# MDR32F2C10 register map
File version: 1.0.1
Registers are 32-bit, read-write, no defined reset value unless marked. A register's access mark holds for its fields unless they carry their own. Offsets are from the block's base; [hi:lo] are bit positions; {n}, {i} and the like mark numbered series.

## MDR_CANFD — MDR_CANFD description
Base 0x40086000
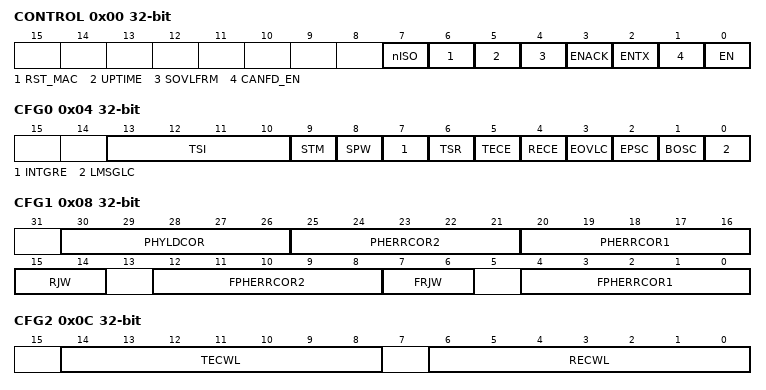
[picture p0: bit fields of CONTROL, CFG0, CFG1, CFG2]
0x00 CONTROL — control Registr upravlenija
  [7] nISO — CRC calculation mode for CANFD packets. 1 - CRC calculation according to standard Bosch, 0 - CRC calculation according to standard ISO
  [6] RST_MAC — Reset MAC module. Reset MAC of CAN.
  [5] UPTIME — Update Time. Set to inactive state by hardware CURTIMEHo and CURTIMELo. Set to inactive state by hardware.
  [4] SOVLFRM — Send Overload Frame. Set to inactive state by hardware.
  [3] ENACK — Enable Acknoledge. Allow ACK to be sent in response to self packets
  [2] ENTX — Enable Transmitter. Allow packet transmission
  [1] CANFD_EN — Enable CAN FD format. Permission to work in CAN FD format
  [0] EN — Enable. Work permit
0x04 CFG0 — Conﬁguration register №0
  [13:10] TSI — Timestamp Increment. 1 - 1. 2 - 10. 4 - 100. 8 - 1000.
  [9] STM — Self-transmit Mode.
  [8] SPW — Sample Width. Bit sets the sampling mode of the bit: 0 - one point 1 - three points
  [7] INTGRE — Integrating Enable. Wait or not 11 recessive bits after power on (CTRL.EN → 1)
  [6] TSR — Timestamp Reset. Counter reset.
  [5] TECE — TECE Enable. TECE counter permission
  [4] RECE — RECE Enable. RECE counter permission
  [3] EOVLC — EOVLC Enable. EOVLC counter permission
  [2] EPSC — EPSC Enable. EPSC counter permission
  [1] BOSC — BOSC Enable. BOSC counter permission
  [0] LMSGLC — LMSGLC Enable. LMSGLC counter permission
0x08 CFG1 — Conﬁguration register №1
  [30:26] PHYLDCOR — PROPSEG - Compensation of the physical delay of the line
  [25:21] PHERRCOR2 — SEG2_N - Second phase error compensation register
  [20:16] PHERRCOR1 — SEG1_N - First phase error compensation register
  [15:14] RJW — RJW_N - (Re-)Synchronization Jump Width.
  [12:8] FPHERRCOR2 — SEG2_D - Second phase error compensation register (Fast Prescaler)
  [7:6] FRJW — RJW_D - Fast (Re-)Synchronization Jump Width.
  [4:0] FPHERRCOR1 — SEG1_D - First phase error compensation register (Fast Prescaler)
0x0C CFG2 — Conﬁguration register №2
  [14:8] TECWL — The level of the warning signal on reaching or exceeding the value of the TEC counter. When the value of this counter reaches or exceeds the warning level, the corresponding bit in the ST register is set and the EOVLC counter is incremented.
  [6:0] RECWL — The level of the warning signal on reaching or exceeding the value of the REC counter. When the value of this counter reaches or exceeds the warning level, the corresponding bit in the ST register is set and the EOVLC counter is incremented.
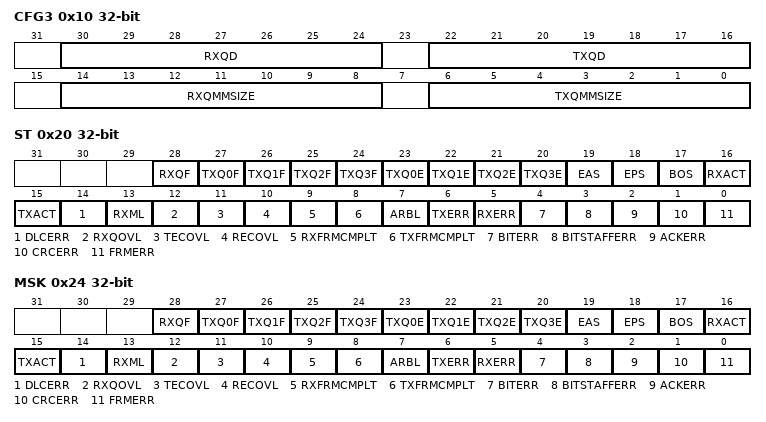
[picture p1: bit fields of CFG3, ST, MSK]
0x10 CFG3 — Conﬁguration register №3
  [30:24] RXQD — receiver queue size. Size for the entire receive queue (default = 96 messages)
  [22:16] TXQD — transmitter queue size. Size for all transmission queues (default = 96 messages)
  [14:8] RXQMMSIZE — receiver queue maximum message size. The maximum size of receive queue messages [0:64]. By default, the maximum is set (size only for the data field).
  [6:0] TXQMMSIZE — transmitter queue maximum message size. The maximum size of transmission queue messages [0:64]. By default, the maximum is set (size only for the data field).
0x14 RXFCFG — receiver ﬁlters conﬁguration. Filter configuration register for incoming messages
  [15:0] FM — Filter Mask. 0 - filter is off
0x18 PRSC — Prescaler register
  [9:0] BRP — Baud-Rate Prescaler.
0x1C FPRSC — Fast prescaler register
  [9:0] FBRP — Fast Baud-Rate Prescaler.
0x20 ST — statuses Registr statusa
  [28] RXQF — (f) Receiver queue full. There is no place to receive one more packet
  [27-n] TXQ{n}F (n=0..3) — (f) Transmitter queue {n} is full
  [23-n] TXQ{n}E (n=0..3) — (f) Transmitter queue {n} is empty
  [19] EAS — (f) CAN controller is in Error Active State
  [18] EPS — (f) CAN controller is in Error Passive State
  [17] BOS — (f) CAN controller is in Bus Off State
  [16] RXACT — (f) Receiving message in progress
  [15] TXACT — (f) Message transmission in progress
  [14] DLCERR — (e) DLC error. Occurs during receiving if the DLC of the received packet is greater than the user-specified value in RXQMMSIZE. Occurs during transmission if the DLC of the transmitted packet is greater than the size specified in TXQMMSIZE.
  [13] RXML — (e) The last message in the buffer was rewritten, because the internal buffers are not empty, it was not possible to move their contents into the system memory because it was busy.
  [12] RXQOVL — (e) Receive queue is full (one or two messages are in buffers)
  [11] TECOVL — (e) TEC counter has reached or exceeded the specified maximum
  [10] RECOVL — (e) REC counter has reached or exceeded the specified maximum
  [9] RXFRMCMPLT — (e) Message fully accepted
  [8] TXFRMCMPLT — (e) Message transmission complete
  [7] ARBL — (e) Loss of arbitration
  [6] TXERR — (e) Transmission error
  [5] RXERR — (e) Receive error
  [4] BITERR — (e) Bit transfer error
  [3] BITSTAFFERR — (e) Bit-straffing error
  [2] ACKERR — (e) No signal acknowledge
  [1] CRCERR — (e) CRC count error
  [0] FRMERR — (e) Message format error on line
0x24 MSK — Mask register
  [28] RXQF — (f) Receiver queue full. There is no place to receive one more packet
  [27-n] TXQ{n}F (n=0..3) — (f) Transmitter queue {n} full
  [23-n] TXQ{n}E (n=0..3) — (f) Transmitter queue {n} empty
  [19] EAS — (f) CAN controller is in error active state
  [18] EPS — (f) CAN controller is in error passive state
  [17] BOS — (f) CAN controller is in bus off state
  [16] RXACT — (f) Message transmission in progress idet priem soobszenija
  [15] TXACT — (f) Message transmission in progress
  [14] DLCERR — (e) DLC error. Occurs during receiving if the DLC of the received packet is greater than the user-specified value in RXQMMSIZE. Occurs during transmission if the DLC of the transmitted packet is greater than the size specified in TXQMMSIZE.
  [13] RXML — (e) The last message in the buffer was rewritten, because the internal buffers are not empty, it was not possible to move their contents into the system memory because it was busy.i
  [12] RXQOVL — (e) Receive queue is full (one or two messages are in buffers)
  [11] TECOVL — (e) TEC counter has reached or exceeded the specified maximum
  [10] RECOVL — (e) REC counter has reached or exceeded the specified maximum
  [9] RXFRMCMPLT — (e) Message fully accepted
  [8] TXFRMCMPLT — (e) Message transmission complete
  [7] ARBL — (e) Loss of arbitration
  [6] TXERR — (e) Transmission error
  [5] RXERR — (e) Receive error
  [4] BITERR — (e) Bit transfer error
  [3] BITSTAFFERR — (e) Bit-straffing error
  [2] ACKERR — (e) No signal acknowledge
  [1] CRCERR — (e) CRC count error
  [0] FRMERR — (e) Message format error on line
0x28 RXBADDR — Receiver queue base address
{0x2C+4i} TXBADDR{i} (i=0..3) — Transmitter queue {i} base address
0x3C CURTIMEHi — curent time counter high-order. The obsolete counter current time register, upper part
0x40 CURTIMELo — curent time counter low. The obsolete counter current time register, lower part
0x50 RXQCTRL0 — Receiver queue 0 control. Receive queue №0 control and status register 0
0x54 RXQCTRL1 — Receiver queue 1 control. Receive queue №0 control and status register 1
{0x58+4i} TXQCTRL{i:02} (i=0..2) — Transmitter queue 0 control {i}. Transmission queue №0 control and status register {i}
{0x3C+4i} TXQCTRL{i} (i=10..12) — Transmitter queue 1 control {i-10}. Transmission queue №1 control and status register {i-10}
{0x20+4i} TXQCTRL{i} (i=20..22) — Transmitter queue 2 control {i-20}. Transmission queue №2 control and status register {i-20}
{0x4+4i} TXQCTRL{i} (i=30..32) — Transmitter queue 3 control {i-30}. Transmission queue №3 control and status register {i-30}
{0x88+4i} TXRCTRL{i:02} (i=0..2) — Transmitter revoke 0 control {i}. Transmit queue №0 cancel register {i}
{0x6C+4i} TXRCTRL{i} (i=10..12) — Transmitter revoke 1 control {i-10}. Transmit queue №1 cancel register {i-10}
{0x50+4i} TXRCTRL{i} (i=20..22) — Transmitter revoke 2 control {i-20}. Transmit queue №2 cancel register {i-20}
{0x34+4i} TXRCTRL{i} (i=30..32) — Transmitter revoke 3 control {i-30}. Transmit queue №3 cancel register {i-30}
{0xC0+4i} RXF{i:02} (i=0..15) — Receiver ﬁlter {i}. Incoming message filter {i} register
{0x100+4i} RXFMSK{i:02} (i=0..15) — Receiver ﬁlter {i} mask. Incoming message filter {i} mask register
0x140 TECE — Transmit error counter extended. Counter of channel errors during message transmission (except for arbitration errors)
0x144 RECE — Receive error counter extended. Counter of channel errors when receiving a message (except for arbitration errors)
0x148 TEC — Transmit error curent counter. Current number of channel errors during message transmission
0x14C REC — Receive error curent counter. Current number of channel errors during message receiving
0x150 EOVLC — Error overload counter. Counter for exceeding TEC or REC "warning level"
0x154 EPSC — Error-passive state counter. Counter of the transition of the channel part of the CAN controller to «error passive» state
0x158 BOSC — Bus oﬀ state counter. Counter of the transition of the channel part of the CAN controller to «bus oﬀ» state
0x15C LMSGLC — Lost message counter. Discarded received messages counter due to receive queue overflow
